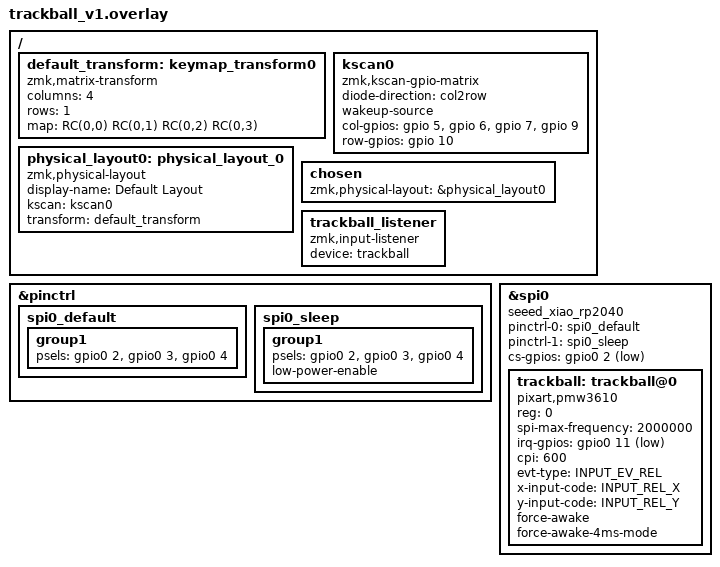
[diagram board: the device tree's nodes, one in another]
#include <dt-bindings/zmk/matrix_transform.h> // Put this with the other includes at the top of your overlay

/ {
    default_transform: keymap_transform0 {
        compatible = "zmk,matrix-transform";
        columns = <4>; // Length of the "col-gpios" array
        rows = <1>; // Length of the "row-gpios" array
        map = <
        //   Key 1 | Key 2 | Key 3 | Key 4
            RC(0,0) RC(0,1) RC(0,2)  RC(0,3)
        >;
    };
};

/ {
    kscan0: kscan0 {
        compatible = "zmk,kscan-gpio-matrix";
        diode-direction = "col2row";
        wakeup-source;

        col-gpios
            = <&gpio 5 GPIO_ACTIVE_HIGH>
            , <&gpio 6 GPIO_ACTIVE_HIGH>
            , <&gpio 7 GPIO_ACTIVE_HIGH>
            , <&gpio 9 GPIO_ACTIVE_HIGH>
            ;

        row-gpios
            = <&gpio 10 (GPIO_ACTIVE_HIGH | GPIO_PULL_DOWN)>
            ;
    };
};

/ {
    physical_layout0: physical_layout_0 { // First physical layout, use different naming for other layouts
        compatible = "zmk,physical-layout";
        display-name = "Default Layout";
        kscan = <&kscan0>; // Label of the kscan node, optional if all layouts use the same
        transform = <&default_transform>; // Label of the matrix transform for this layout
    };
};

/ {
    chosen {
        zmk,physical-layout = &physical_layout0;
        // Other chosen items
    };
};


&pinctrl {
    spi0_default: spi0_default {
        group1 {
            psels = <
                &gpio0 2  /* SCK */
                &gpio0 3  /* MOSI */
                &gpio0 4  /* MISO */
            >;
        };
    };

    spi0_sleep: spi0_sleep {
        group1 {
            psels = <
                &gpio0 2  /* SCK */
                &gpio0 3  /* MOSI */
                &gpio0 4  /* MISO */
            >;
            low-power-enable;
        };
    };
};

#include <zephyr/dt-bindings/input/input-event-codes.h>

&spi0 {
    status = "okay";
    compatible = "seeed_xiao_rp2040";   /* Seeed XIAO RP2040 焊靛 */
    pinctrl-0 = <&spi0_default>;
    pinctrl-1 = <&spi0_sleep>;
    pinctrl-names = "default", "sleep";
    cs-gpios = <&gpio0 2 GPIO_ACTIVE_LOW>; /* CS 巧 瘤沥 */

    trackball: trackball@0 {
        status = "okay";
        compatible = "pixart,pmw3610";
        reg = <0>;
        spi-max-frequency = <2000000>;
        irq-gpios = <&gpio0 11 (GPIO_ACTIVE_LOW | GPIO_PULL_UP)>;
        cpi = <600>;
        // swap-xy; /* optional */
        // invert-x; /* optional */
        // invert-y; /* optional */
        evt-type = <INPUT_EV_REL>;
        x-input-code = <INPUT_REL_X>;
        y-input-code = <INPUT_REL_Y>;

        force-awake;
        /* keep the sensor awake while ZMK activity state is ACTIVE,
           fallback to normal downshift mode after ZMK goes into IDLE / SLEEP mode.
           thus, the sensor would be a `wakeup-source` */

        force-awake-4ms-mode;
        /* while force-awake is acitvated, enable this mode to force sampling per 
           4ms, where the default sampling rate is 8ms. */
        /* NOTE: apply this mode if you need 250Hz with direct USB connection. */
    };
};

/ {
  trackball_listener {
    compatible = "zmk,input-listener";
    device = <&trackball>;
  };
};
